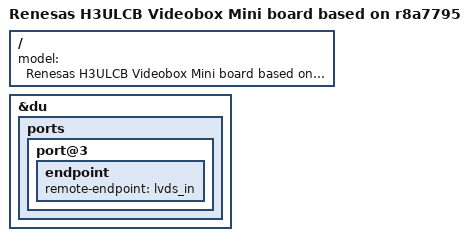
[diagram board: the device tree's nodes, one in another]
/*
 * Device Tree Source for the H3ULCB Videobox Mini board on r8a7795 ES1.x
 *
 * Copyright (C) 2017 Cogent Embedded, Inc.
 *
 * This file is licensed under the terms of the GNU General Public License
 * version 2.  This program is licensed "as is" without any warranty of any
 * kind, whether express or implied.
 */

#include "r8a7795-es1-h3ulcb.dts"
#include "ulcb-vbm.dtsi"

/ {
	model = "Renesas H3ULCB Videobox Mini board based on r8a7795";
};

&du {
	ports {
		port@3 {
			endpoint {
				remote-endpoint = <&lvds_in>;
			};
		};
	};
};
